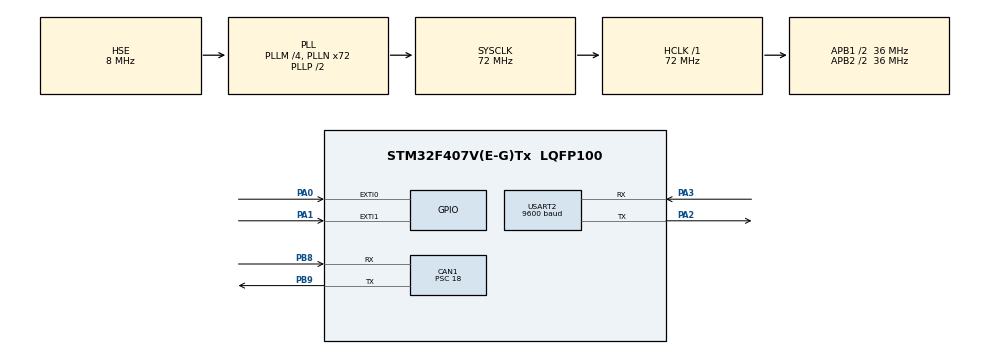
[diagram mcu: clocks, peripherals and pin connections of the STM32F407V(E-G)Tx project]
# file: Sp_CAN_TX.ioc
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CAN1.BS2=CAN_BS2_2TQ
CAN1.CalculateBaudRate=500000
CAN1.CalculateTimeBit=2000
CAN1.CalculateTimeQuantum=500.0
CAN1.Prescaler=18
Mcu.Family=STM32F4
Mcu.Name=STM32F407V(E-G)Tx
Mcu.Package=LQFP100
NVIC.EXTI0_IRQn=true\:0\:0\:false\:false\:true\:true\:true\:true
NVIC.EXTI1_IRQn=true\:0\:0\:false\:false\:true\:true\:true\:true
NVIC.PriorityGroup=NVIC_PRIORITYGROUP_0
NVIC.RCC_IRQn=true\:0\:0\:false\:false\:true\:true\:false\:true
NVIC.TIM2_IRQn=true\:0\:0\:false\:false\:true\:true\:true\:true
NVIC.USART2_IRQn=true\:0\:0\:false\:false\:true\:true\:true\:true
PA0-WKUP.Signal=GPXTI0
PA1.Signal=GPXTI1
PA2.Mode=Asynchronous
PA2.Signal=USART2_TX
PA3.Mode=Asynchronous
PA3.Signal=USART2_RX
PB8.Mode=CAN_Activate
PB8.Signal=CAN1_RX
PB9.Mode=CAN_Activate
PB9.Signal=CAN1_TX
PH0-OSC_IN.Mode=HSE-External-Oscillator
PH0-OSC_IN.Signal=RCC_OSC_IN
PH1-OSC_OUT.Mode=HSE-External-Oscillator
PH1-OSC_OUT.Signal=RCC_OSC_OUT
ProjectManager.HeapSize=0x200
ProjectManager.StackSize=0x400
ProjectManager.TargetToolchain=STM32CubeIDE
RCC.48MHZClocksFreq_Value=20571428.57142857
RCC.AHBFreq_Value=72000000
RCC.APB1CLKDivider=RCC_HCLK_DIV2
RCC.APB1Freq_Value=36000000
RCC.APB1TimFreq_Value=72000000
RCC.APB2CLKDivider=RCC_HCLK_DIV2
RCC.APB2Freq_Value=36000000
RCC.APB2TimFreq_Value=72000000
RCC.CortexFreq_Value=72000000
RCC.HCLKFreq_Value=72000000
RCC.HSE_VALUE=8000000
RCC.HSI_VALUE=16000000
RCC.LSE_VALUE=32768
RCC.PLLM=4
RCC.PLLN=72
RCC.PLLQ=7
RCC.PLLSourceVirtual=RCC_PLLSOURCE_HSE
RCC.SYSCLKFreq_VALUE=72000000
RCC.SYSCLKSource=RCC_SYSCLKSOURCE_PLLCLK
RCC.VCOOutputFreq_Value=144000000
TIM2.Period=0xFFFFFFFF
TIM2.Prescaler=84
USART2.BaudRate=9600
USART2.VirtualMode=VM_ASYNC
VP_TIM2_VS_ClockSourceINT.Mode=Internal
board=STM32F407G-DISC1

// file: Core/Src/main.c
/* USER CODE BEGIN Header */
/**
  ******************************************************************************
  * @file           : main.c
  * @brief          : Main program body
  ******************************************************************************
  */
/* USER CODE END Header */
#include "main.h"

CAN_HandleTypeDef hcan1;

TIM_HandleTypeDef htim2;

UART_HandleTypeDef huart2;

/* USER CODE BEGIN PV */
volatile uint32_t T1 = 0, T2 = 0;
volatile uint8_t flag = 0; // To track IR sensor activation
char buffer[50];  // Buffer for UART transmission
CAN_TxHeaderTypeDef TxHeader;  // CAN TX Header
uint8_t TxData[8];             // CAN TX Data
uint32_t TxMailbox;            // CAN Tx Mailbox
/* USER CODE END PV */

void SystemClock_Config(void);
static void MX_GPIO_Init(void);
static void MX_CAN1_Init(void);
static void MX_TIM2_Init(void);
static void MX_USART2_UART_Init(void);

int main(void)
{

  /* MCU Configuration--------------------------------------------------------*/

  /* Reset of all peripherals, Initializes the Flash interface and the Systick. */
  HAL_Init();

  /* Configure the system clock */
  SystemClock_Config();

  /* Initialize all configured peripherals */
  MX_GPIO_Init();
  MX_CAN1_Init();
  MX_TIM2_Init();
  MX_USART2_UART_Init();

  /* Infinite loop */
  while (1)
  {

  }
}

void SystemClock_Config(void)
{
  RCC_OscInitTypeDef RCC_OscInitStruct = {0};
  RCC_ClkInitTypeDef RCC_ClkInitStruct = {0};

  /** Configure the main internal regulator output voltage
  */
  __HAL_RCC_PWR_CLK_ENABLE();
  __HAL_PWR_VOLTAGESCALING_CONFIG(PWR_REGULATOR_VOLTAGE_SCALE1);

  /** Initializes the RCC Oscillators according to the specified parameters
  * in the RCC_OscInitTypeDef structure.
  */
  RCC_OscInitStruct.OscillatorType = RCC_OSCILLATORTYPE_HSE;
  RCC_OscInitStruct.HSEState = RCC_HSE_ON;
  RCC_OscInitStruct.PLL.PLLState = RCC_PLL_ON;
  RCC_OscInitStruct.PLL.PLLSource = RCC_PLLSOURCE_HSE;
  RCC_OscInitStruct.PLL.PLLM = 4;
  RCC_OscInitStruct.PLL.PLLN = 72;
  RCC_OscInitStruct.PLL.PLLP = RCC_PLLP_DIV2;
  RCC_OscInitStruct.PLL.PLLQ = 7;
  if (HAL_RCC_OscConfig(&RCC_OscInitStruct) != HAL_OK)
  {
    Error_Handler();
  }

  /** Initializes the CPU, AHB and APB buses clocks
  */
  RCC_ClkInitStruct.ClockType = RCC_CLOCKTYPE_HCLK|RCC_CLOCKTYPE_SYSCLK
                              |RCC_CLOCKTYPE_PCLK1|RCC_CLOCKTYPE_PCLK2;
  RCC_ClkInitStruct.SYSCLKSource = RCC_SYSCLKSOURCE_PLLCLK;
  RCC_ClkInitStruct.AHBCLKDivider = RCC_SYSCLK_DIV1;
  RCC_ClkInitStruct.APB1CLKDivider = RCC_HCLK_DIV2;
  RCC_ClkInitStruct.APB2CLKDivider = RCC_HCLK_DIV2;

  if (HAL_RCC_ClockConfig(&RCC_ClkInitStruct, FLASH_LATENCY_2) != HAL_OK)
  {
    Error_Handler();
  }
}

static void MX_CAN1_Init(void)
{

  hcan1.Instance = CAN1;
  hcan1.Init.Prescaler = 18;
  hcan1.Init.Mode = CAN_MODE_NORMAL;
  hcan1.Init.SyncJumpWidth = CAN_SJW_1TQ;
  hcan1.Init.TimeSeg1 = CAN_BS1_1TQ;
  hcan1.Init.TimeSeg2 = CAN_BS2_2TQ;
  hcan1.Init.TimeTriggeredMode = DISABLE;
  hcan1.Init.AutoBusOff = DISABLE;
  hcan1.Init.AutoWakeUp = DISABLE;
  hcan1.Init.AutoRetransmission = DISABLE;
  hcan1.Init.ReceiveFifoLocked = DISABLE;
  hcan1.Init.TransmitFifoPriority = DISABLE;
  if (HAL_CAN_Init(&hcan1) != HAL_OK)
  {
    Error_Handler();
  }

}

static void MX_TIM2_Init(void)
{

  TIM_ClockConfigTypeDef sClockSourceConfig = {0};
  TIM_MasterConfigTypeDef sMasterConfig = {0};

  htim2.Instance = TIM2;
  htim2.Init.Prescaler = 84;
  htim2.Init.CounterMode = TIM_COUNTERMODE_UP;
  htim2.Init.Period = 0xFFFFFFFF;
  htim2.Init.ClockDivision = TIM_CLOCKDIVISION_DIV1;
  htim2.Init.AutoReloadPreload = TIM_AUTORELOAD_PRELOAD_DISABLE;
  if (HAL_TIM_Base_Init(&htim2) != HAL_OK)
  {
    Error_Handler();
  }
  sClockSourceConfig.ClockSource = TIM_CLOCKSOURCE_INTERNAL;
  if (HAL_TIM_ConfigClockSource(&htim2, &sClockSourceConfig) != HAL_OK)
  {
    Error_Handler();
  }
  sMasterConfig.MasterOutputTrigger = TIM_TRGO_RESET;
  sMasterConfig.MasterSlaveMode = TIM_MASTERSLAVEMODE_DISABLE;
  if (HAL_TIMEx_MasterConfigSynchronization(&htim2, &sMasterConfig) != HAL_OK)
  {
    Error_Handler();
  }

}

static void MX_USART2_UART_Init(void)
{

  huart2.Instance = USART2;
  huart2.Init.BaudRate = 9600;
  huart2.Init.WordLength = UART_WORDLENGTH_8B;
  huart2.Init.StopBits = UART_STOPBITS_1;
  huart2.Init.Parity = UART_PARITY_NONE;
  huart2.Init.Mode = UART_MODE_TX_RX;
  huart2.Init.HwFlowCtl = UART_HWCONTROL_NONE;
  huart2.Init.OverSampling = UART_OVERSAMPLING_16;
  if (HAL_UART_Init(&huart2) != HAL_OK)
  {
    Error_Handler();
  }

}

static void MX_GPIO_Init(void)
{
  GPIO_InitTypeDef GPIO_InitStruct = {0};

  /* GPIO Ports Clock Enable */
  __HAL_RCC_GPIOH_CLK_ENABLE();
  __HAL_RCC_GPIOA_CLK_ENABLE();
  __HAL_RCC_GPIOB_CLK_ENABLE();

  /*Configure GPIO pins : PA0 PA1 */
  GPIO_InitStruct.Pin = GPIO_PIN_0|GPIO_PIN_1;
  GPIO_InitStruct.Mode = GPIO_MODE_IT_RISING;
  GPIO_InitStruct.Pull = GPIO_NOPULL;
  HAL_GPIO_Init(GPIOA, &GPIO_InitStruct);

  /* EXTI interrupt init*/
  HAL_NVIC_SetPriority(EXTI0_IRQn, 0, 0);
  HAL_NVIC_EnableIRQ(EXTI0_IRQn);

  HAL_NVIC_SetPriority(EXTI1_IRQn, 0, 0);
  HAL_NVIC_EnableIRQ(EXTI1_IRQn);

}

void Error_Handler(void)
{
  __disable_irq();
  while (1)
  {
  }
}
